# GAP8 register map
Vendor: GreenWaves Technologies SAS; Series: GAP8; File version: 1.3.1
CPU: other r1p0, little endian, MPU, no FPU, I-cache, DTCM, false interrupt priority bits
Registers are 32-bit, read-write, reset 0x0 unless marked. A register's access mark holds for its fields unless they carry their own. Offsets are from the block's base; [hi:lo] are bit positions; 'fields as' and 'values as' point back to an identical list.

## dlc_bridge — PMU DLC bridge
Base 0x1A107000
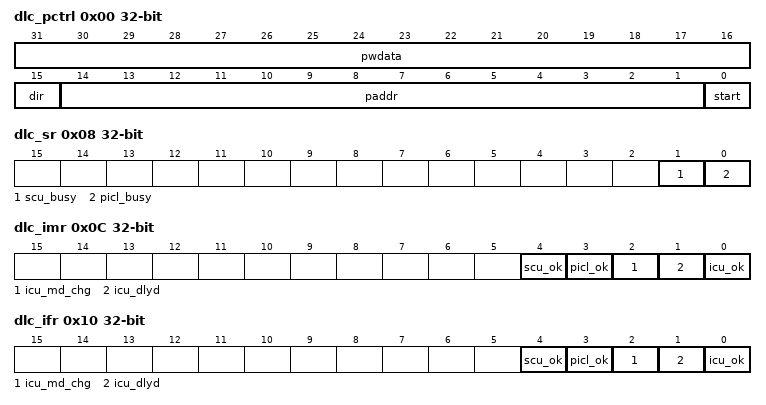
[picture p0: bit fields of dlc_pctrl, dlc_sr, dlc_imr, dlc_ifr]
0x00 dlc_pctrl — DLC PICL control register.
  [31:16] pwdata — Data to write on the PICL bus.
  [15] dir — Direction of the transfer on the PICL bus.
    0=write_operation (set to write operation); 1=read_operation (set to read operation)
  [14:1] paddr — Address of the transfer on the PICL bus.
  [0] start — Start of PICL access sequence. A rising edge of the start bit starts a PICL picl transfer. Start bit remains high until the end of the sequence, which means that no new access can be performed if an access is on going.
0x04 dlc_prdata ro — DLC PICL data read register
  [7:0] prdata — Data read on the PICL bus. This data is valid after a PICL read operation, when the picl_busy bit of the DLC_SR register becomes low.
0x08 dlc_sr ro — DLC Status register
  [1] scu_busy — SCU busy. This bit is set to 1'b1 if when a SCU sequence is on going. This bit is cleared at the end of the sequence.
  [0] picl_busy — PICL busy. This bit is set to 1'b1 if when a transfer is ongoing on the PICL bus. This bit is cleared at the end of the transfer.
0x0C dlc_imr — DLC Interrupt mask register
  [all] fields
    0=mask_cleared (set to mask cleared); 1=mask_set (set to mask set)
  [4] scu_ok — Mask of scu_ok interrupt.
  [3] picl_ok — Mask of picl_ok interrupt.
  [2] icu_md_chg — Mask of icu_mode_changed interrupt.
  [1] icu_dlyd — Mask of icu_delayed interrupt.
  [0] icu_ok — Mask of icu_ok interrupt.
0x10 dlc_ifr ro — DLC Interrupt flag register
  [4] scu_ok — Set to 1'b1 when SCU sequence is finished. Cleared by writing 1 to bit 4 of the DLC_IFR register.
  [3] picl_ok — Set to 1'b1 when PICL transfer is finish. Cleared by writing 1 to bit 3 of the DLC_IFR register.
  [2] icu_md_chg — Set to 1'b1 when at least one of the bit of the DLC_IMCIFR register is set. Cleared by reading the DCL_IMCIFR register.
  [1] icu_dlyd — Set to 1'b1 when at least one of the bit of the DLC_IDIFR register is set. Cleared by reading the DCL_IDIFR register.
  [0] icu_ok — Set to 1'b1 when at least one of the bit of the DLC_IOIFR register is set. Cleared by reading the DCL_IOIFR register.
0x14 dlc_ioifr ro — DLC icu_ok interrupt flag register
  [31:1] icu_ok_flgs — Flags of the icu_ok interrupts. Bit[x] is set to 1'b1 when a rising edge of the signal i_icu_ok_irq[x] occurs and MSP is requester of the change mode order of the ICU[x]. A read of this register clears the register and the bit icu_ok_flag of the DLC_IFR register.
0x18 dlc_idifr ro — DLC icu_delayed interrupt flag register
  [31:1] icu_dlyd_flgs — Flags of the icu_delayed interrupts. Bit[x] is set to 1'b1 when a rising edge of the signal i_icu_delayed_irq[x] occurs and MSP is requester of the change mode order of the ICU[x]. A read this register clears the register and the bit icu_delayed_flag of the DLC_IFR register.
0x1C dlc_imcifr ro — DLC icu_mode_changed interrupt flag register
  [31:1] icu_md_chng_flgs — Flags of the icu_mode_changed interrupts. Bit [x] is set to 1'b1 when a rising edge of the signal i_icu_mode_changed_irq[x] occurs. A read this register clears the register and the bit icu_mode_changed_flag of the DLC_IFR register.

## rtc — RealTime Counter
Base 0x1A108000
0x00 apb_sr ro — RTC APB status register.
  [1:0] int — APB interrupt status bitfield
    on read: 0=No interruption has been requested; 1=Interruption requested
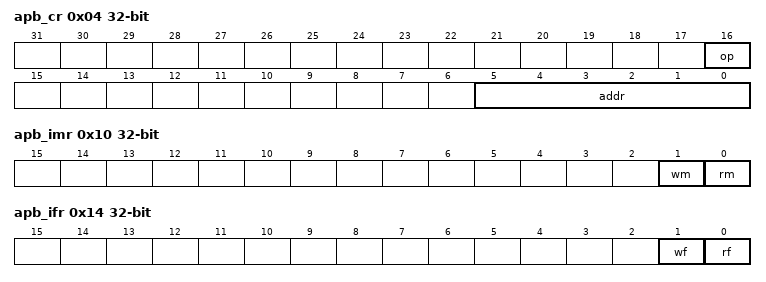
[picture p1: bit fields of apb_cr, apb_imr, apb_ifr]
0x04 apb_cr — RTC APB control register.
  [16] op — Indirect access operation configuration bitfield
    0=apb_read_operation (set to APB read operation); 1=APB write operation
  [5:0] addr — Indirect address configuration bitfield.
0x08 apb_dr — RTC APB data register.
  [31:0] data — Indirect data bitfield.
0x0C apb_icr — RTC APB interrupt control register.
  [1:0] mode — APB interrupt signal mode configuration bitfield
    0=APB interrupt is a high level signal; 1=APB interrupt is a low level signal; 2=APB interrupt is a high level pulse of 1 PCLK duration; 3=APB interrupt is a low level pulse of 1 PCLK duration
0x10 apb_imr — RTC APB interrupt mask register.
  [1] wm — APB write operation interrupt mask bitfield
    0=enabled (feature is enabled); 1=disabled (feature is disabled)
  [0] rm — APB read operation interrupt mask bitfield
    values as wm
0x14 apb_ifr — RTC APB interrupt flag register.
  [1] wf — APB write operation status flag bitfield
    0=nothing (set to nothing); 1=write operation done
  [0] rf — APB read operation status flag bitfield
    0=nothing (set to nothing); 1=read operation done and requested indirect data is available
